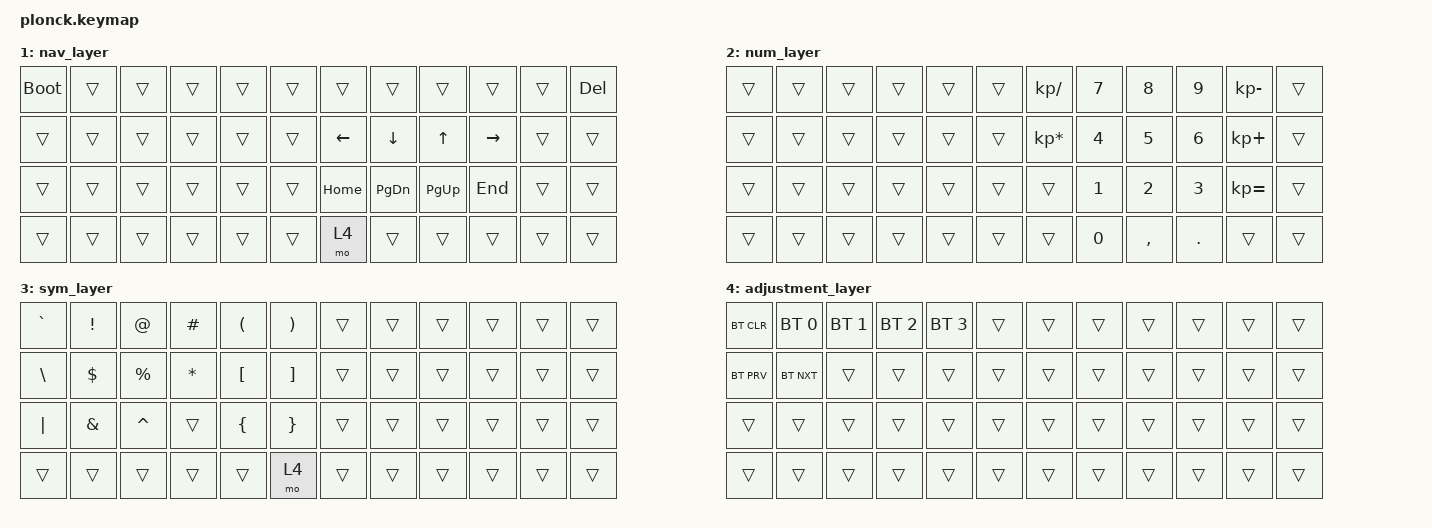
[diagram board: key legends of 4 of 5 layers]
/*
 * Copyright (c) 2021 swampmonster
 *
 * SPDX-License-Identifier: MIT
 */

#include <behaviors.dtsi>
#include <dt-bindings/zmk/keys.h>
#include <dt-bindings/zmk/bt.h>

/ {
  combos { };

  behaviors { };

  keymap {
    compatible = "zmk,keymap";

    default_layer {
      bindings = <
        &gresc    &kp Q      &kp W      &kp E       &kp R       &kp T         &kp Y     &kp U       &kp I       &kp O      &kp P         &kp BSPC
        &kp TAB   &kp A      &kp S      &kp D       &kp F       &kp G         &kp H     &kp J       &kp K       &kp L      &kp SEMI      &kp SQT
        &kp LSHFT &kp Z      &kp X      &kp C       &kp V       &kp B         &kp N     &kp M       &kp COMMA   &kp DOT    &kp FSLH      &kp RET
        &kp LCTRL &trans     &kp LALT   &kp LCMD    &mo 2       &kp SPC       &mo 1     &kp RCMD    &kp RALT    &kp RCTRL  &trans
        >;
    };

    nav_layer {
      bindings = <
        &bootloader &trans &trans &trans &trans &trans &trans   &trans        &trans    &trans    &trans &kp DEL
        &trans      &trans &trans &trans &trans &trans &kp LEFT &kp DOWN      &kp UP    &kp RIGHT &trans &trans
        &trans      &trans &trans &trans &trans &trans &kp HOME &kp PG_DN     &kp PG_UP &kp END   &trans &trans
        &trans      &trans &trans &trans &trans &trans &mo 4    &trans        &trans    &trans    &trans &trans
        >;
    };

    num_layer {
      bindings = <
        &trans &trans &trans &trans &trans &trans &kp KP_SLASH    &kp N7 &kp N8    &kp N9  &kp KP_MINUS &trans
        &trans &trans &trans &trans &trans &trans &kp KP_MULTIPLY &kp N4 &kp N5    &kp N6  &kp KP_PLUS  &trans
        &trans &trans &trans &trans &trans &trans &trans          &kp N1 &kp N2    &kp N3  &kp KP_EQUAL &trans
        &trans &trans &trans &trans &trans &trans &trans          &kp N0 &kp COMMA &kp DOT &trans       &trans
        >;
    };

    sym_layer {
      bindings = <
        &kp GRAVE &kp EXCL  &kp AT    &kp HASH  &kp LPAR &kp RPAR &trans &trans &trans &trans &trans &trans 
        &kp BSLH  &kp DLLR  &kp PRCNT &kp ASTRK &kp LBKT &kp RBKT &trans &trans &trans &trans &trans &trans 
        &kp PIPE  &kp AMPS  &kp CARET &trans    &kp LBRC &kp RBRC &trans &trans &trans &trans &trans &trans 
        &trans    &trans    &trans    &trans    &trans   &mo 4    &trans &trans &trans &trans &trans &trans 
        >;
    };

    adjustment_layer {
      bindings = <
        &bt BT_CLR &bt BT_SEL 0 &bt BT_SEL 1 &bt BT_SEL 2 &bt BT_SEL 3 &trans &trans &trans &trans &trans &trans &trans 
        &bt BT_PRV &bt BT_NXT   &trans       &trans       &trans       &trans &trans &trans &trans &trans &trans &trans 
        &trans     &trans       &trans       &trans       &trans       &trans &trans &trans &trans &trans &trans &trans 
        &trans     &trans       &trans       &trans       &trans       &trans &trans &trans &trans &trans &trans &trans 
        >;
    };
  };
};
